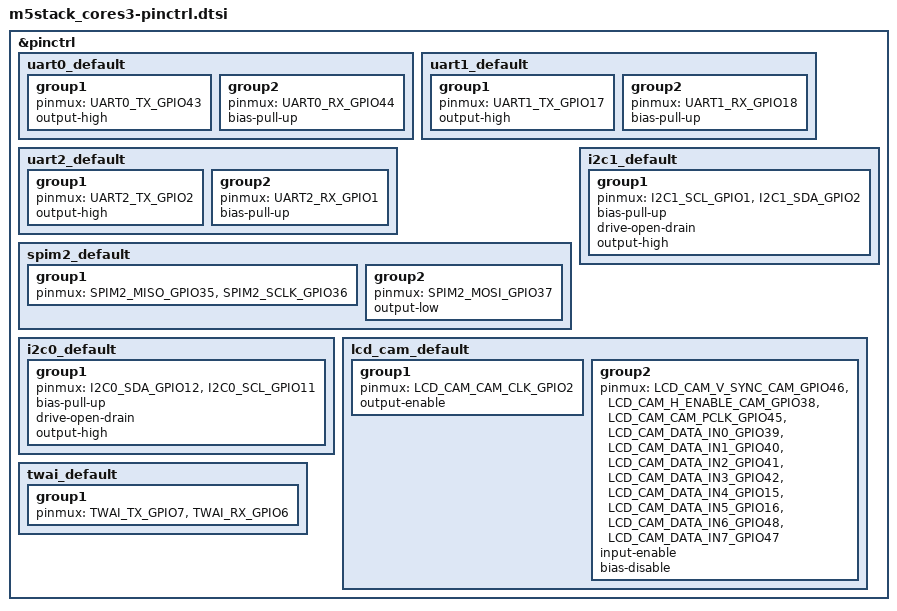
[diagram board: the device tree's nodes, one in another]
/*
 * Copyright (c) 2024 Zhang Xingtao <zhxt@live.cn>
 *
 * SPDX-License-Identifier: Apache-2.0
 */

#include <zephyr/dt-bindings/pinctrl/esp-pinctrl-common.h>
#include <zephyr/dt-bindings/pinctrl/esp32s3-pinctrl.h>
#include <zephyr/dt-bindings/pinctrl/esp32s3-gpio-sigmap.h>

&pinctrl {
	uart0_default: uart0_default {
		group1 {
			pinmux = <UART0_TX_GPIO43>;
			output-high;
		};

		group2 {
			pinmux = <UART0_RX_GPIO44>;
			bias-pull-up;
		};
	};

	uart1_default: uart1_default {
		group1 {
			pinmux = <UART1_TX_GPIO17>;
			output-high;
		};

		group2 {
			pinmux = <UART1_RX_GPIO18>;
			bias-pull-up;
		};
	};

	uart2_default: uart2_default {
		group1 {
			pinmux = <UART2_TX_GPIO2>;
			output-high;
		};

		group2 {
			pinmux = <UART2_RX_GPIO1>;
			bias-pull-up;
		};
	};

	spim2_default: spim2_default {
		group1 {
			pinmux = <SPIM2_MISO_GPIO35>,
				 <SPIM2_SCLK_GPIO36>;
		};

		group2 {
			pinmux = <SPIM2_MOSI_GPIO37>;
			output-low;
		};
	};

	i2c0_default: i2c0_default {
		group1 {
			pinmux = <I2C0_SDA_GPIO12>,
				 <I2C0_SCL_GPIO11>;
			bias-pull-up;
			drive-open-drain;
			output-high;
		};
	};

	i2c1_default: i2c1_default {
		group1 {
			pinmux = <I2C1_SCL_GPIO1>,
				 <I2C1_SDA_GPIO2>;
			bias-pull-up;
			drive-open-drain;
			output-high;
		};
	};

	lcd_cam_default: lcd_cam_default {
		group1 {
			pinmux = <LCD_CAM_CAM_CLK_GPIO2>;
			output-enable;
		};

		group2 {
			pinmux = <LCD_CAM_V_SYNC_CAM_GPIO46>,
				 <LCD_CAM_H_ENABLE_CAM_GPIO38>,
				 <LCD_CAM_CAM_PCLK_GPIO45>,
				 <LCD_CAM_DATA_IN0_GPIO39>,
				 <LCD_CAM_DATA_IN1_GPIO40>,
				 <LCD_CAM_DATA_IN2_GPIO41>,
				 <LCD_CAM_DATA_IN3_GPIO42>,
				 <LCD_CAM_DATA_IN4_GPIO15>,
				 <LCD_CAM_DATA_IN5_GPIO16>,
				 <LCD_CAM_DATA_IN6_GPIO48>,
				 <LCD_CAM_DATA_IN7_GPIO47>;
			input-enable;
			bias-disable;
		};
	};

	twai_default: twai_default {
		group1 {
			pinmux = <TWAI_TX_GPIO7>,
				 <TWAI_RX_GPIO6>;
		};
	};
};
